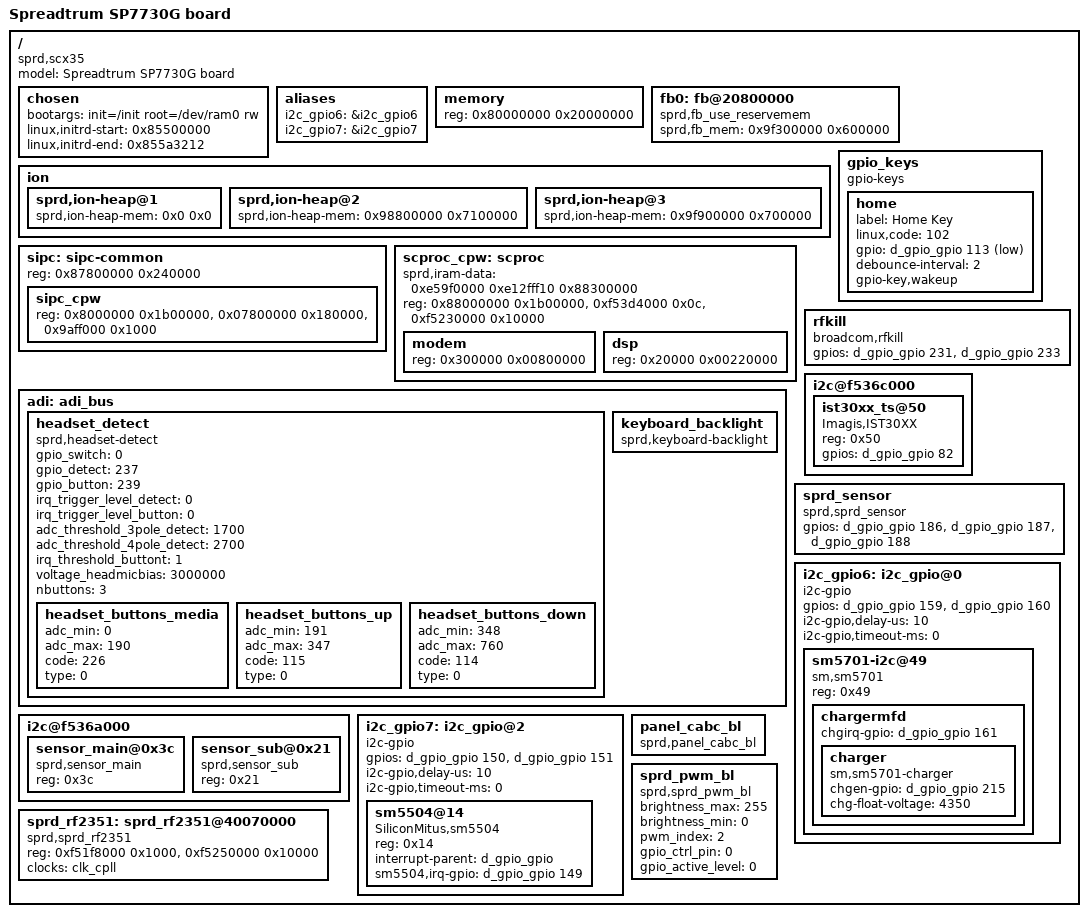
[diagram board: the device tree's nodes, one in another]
/*
 * Copyright (C) 2013 Spreadtrum Communication Incorporated
 *		http://www.spreadtrum.com/
 *
 * This program is free software; you can redistribute it and/or modify
 * it under the terms of the GNU General Public License version 2 as
 * published by the Free Software Foundation.
 */
/dts-v1/;

/* memory reserved for SMEM */
/memreserve/ 0x87800000 0x240000; /* 2MK+256K */

/* memory reserved for CPW modem */
/memreserve/ 0x88000000 0x1b00000; /* 27M */

/* memory reserved for fb */
/memreserve/ 0x9f300000 0x600000; /* 6MK */

/* memory reserved for ION */
/memreserve/ 0x98800000 0x7100000;
/memreserve/ 0x9f900000 0x700000; /* 7MK */

/* /include/ "rt5033.dtsi" */
/include/ "sprd-scx35.dtsi"

/ {
	model = "Spreadtrum SP7730G board";
	compatible = "sprd,scx35";

	chosen {
		bootargs = "init=/init root=/dev/ram0 rw";
		linux,initrd-start = <0x85500000>;
		linux,initrd-end   = <0x855a3212>;
	};

	aliases {
		i2c_gpio6 = &i2c_gpio6;
		i2c_gpio7 = &i2c_gpio7;
		/*i2c_gpio8 = &i2c_gpio8;*/
	};

	memory {
		device_type = "memory";
		reg = <0x80000000 0x20000000>;
	};

	fb0: fb@20800000 {
		sprd,fb_use_reservemem;
		sprd,fb_mem = <0x9f300000 0x600000>;
	};

	ion {
		sprd,ion-heap@1 {
			sprd,ion-heap-mem = <0x0 0x0>;
		};

		sprd,ion-heap@2 {
			sprd,ion-heap-mem = <0x98800000 0x7100000>;
		};

		sprd,ion-heap@3 {
			sprd,ion-heap-mem = <0x9f900000 0x700000>;
		};
	};

	/* sipc initializer */
	sipc: sipc-common {
		reg = <0x87800000 0x240000>; /* <SMEM SIZE>*/
		ranges = <0x8000000 0x88000000 0x1b00000>,
				<0x07800000 0x87800000 0x180000>,
				<0x9aff000 0x89aff000 0x1000>;
		sipc_cpw {
			reg = <0x8000000 0x1b00000> , /* <CP_start_addr size> */
			<0x07800000 0x180000>, /* <SMEM_phy_addr total_size> */
			<0x9aff000 0x1000>; /* smsg ring buffer <base size> */
		};
	};

	scproc_cpw: scproc {
		sprd,iram-data = <0xe59f0000 0xe12fff10 0x88300000>; /* 3rd param equals modem_addr*/
		reg = <0x88000000 0x1b00000>, /* <CP_start_addr total_size> = <+128M 27M> */
			<0xf53d4000 0x0c>, /* <iram1_base size> */
			<0xf5230000 0x10000>; /* <pmu_base size> */
		ranges = <0x300000 0x88300000 0x00800000>,
				<0x20000 0x88020000 0x00220000>;
		modem {
			reg = <0x300000 0x00800000>; /* <modem_addr size> */
		};
		dsp {
			reg = <0x20000 0x00220000>; /* <dsp_addr size>*/
		};
	};

	adi: adi_bus {
		headset_detect {
			compatible = "sprd,headset-detect";
			gpio_switch = <0>;
			gpio_detect = <237>;
			gpio_button = <239>;
			irq_trigger_level_detect = <0>;
			irq_trigger_level_button = <0>;
			adc_threshold_3pole_detect = <1700>;
			adc_threshold_4pole_detect = <2700>;
			irq_threshold_buttont = <1>;
			voltage_headmicbias = <3000000>;
			nbuttons = <3>;
			headset_buttons_media {
				adc_min = <0>;
				adc_max = <190>;
				code = <226>;
				type = <0>;
			};

			headset_buttons_up {
				adc_min = <191>;
				adc_max = <347>;
				code = <115>;
				type = <0>;
			};

			headset_buttons_down {
				adc_min = <348>;
				adc_max =<760>;
				code = <114>;
				type = <0>;
			};
		};

		keyboard_backlight {
			compatible = "sprd,keyboard-backlight";
		};
	};

	gpio_keys {
		compatible = "gpio-keys";
		home {
			label = "Home Key";
			linux,code = <102>;
			gpio = <&d_gpio_gpio 113 1>;
			debounce-interval = <2>;
			gpio-key,wakeup;
		};
	};

	rfkill {
		compatible = "broadcom,rfkill";
		gpios = <&d_gpio_gpio 231 0  /* power */
				&d_gpio_gpio 233 0>;  /* reset */
	};

	i2c@f536c000 { /* TSP */
		ist30xx_ts@50 {
			compatible = "Imagis,IST30XX";
			reg = <0x50>;
			gpios = <&d_gpio_gpio 82 0>; 
		};  
	};

	i2c@f536a000 {
		sensor_main@0x3c{
			compatible = "sprd,sensor_main";
			reg = <0x3c>;
		};
		sensor_sub@0x21{
			compatible = "sprd,sensor_sub";
			reg = <0x21>;
		};
	};

	sprd_sensor {
		compatible  = "sprd,sprd_sensor";
		gpios = <&d_gpio_gpio 186 0   /*reset*/
				&d_gpio_gpio 187 0    /*main*/
				&d_gpio_gpio 188 0>;  /*sub */
	};

	i2c_gpio6: i2c_gpio@0 {
		compatible = "i2c-gpio";
		#address-cells = <1>;
		#size-cells = <0>;
		gpios = <&d_gpio_gpio 159 0 /* sda */
                        &d_gpio_gpio 160 0 >; /* scl */
		i2c-gpio,delay-us = <10>;    /* ~100 kHz */
		i2c-gpio,timeout-ms = <0>;

		sm5701-i2c@49 {
			compatible = "sm,sm5701";
			reg = <0x49>;
                        chargermfd {
                                   chgirq-gpio = <&d_gpio_gpio 161 0>;
                                   charger {
                                           compatible = "sm,sm5701-charger";
                                           chgen-gpio = <&d_gpio_gpio 215 0>;
	                                   chg-float-voltage = <4350>;
                                   };

                        };
		};
	};

	i2c_gpio7: i2c_gpio@2 {
		compatible = "i2c-gpio";
		#address-cells = <1>;
		#size-cells = <0>;
		gpios = <&d_gpio_gpio 150 0 /* sda */
                        &d_gpio_gpio 151 0 >; /* scl */
		i2c-gpio,delay-us = <10>;    /* ~100 kHz */
		i2c-gpio,timeout-ms = <0>;

		sm5504@14 {
			compatible = "SiliconMitus,sm5504";
			reg = <0x14>;
			interrupt-parent = <&d_gpio_gpio>;
			sm5504,irq-gpio = <&d_gpio_gpio 149 0>; 
		};
	};

	sprd_rf2351: sprd_rf2351@40070000{
		compatible  = "sprd,sprd_rf2351";
		reg = <0xf51f8000 0x1000>,		/*RFSPI*/
			<0xf5250000 0x10000>;		/*APB_EB0*/
		clock-names = "clk_cpll";
		clocks = <&clk_cpll>;
	};

	panel_cabc_bl {
		compatible = "sprd,panel_cabc_bl";
	};

	sprd_pwm_bl {
		compatible = "sprd,sprd_pwm_bl";
		brightness_max = <255>;
		brightness_min = <0>;
		pwm_index = <2>;
		gpio_ctrl_pin = <0>;
		gpio_active_level = <0>;
	};
};
